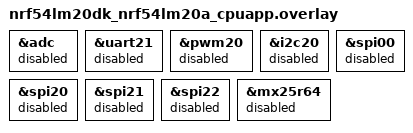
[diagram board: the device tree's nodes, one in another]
/* Copyright (c) 2025 Nordic Semiconductor ASA
 *
 * SPDX-License-Identifier: LicenseRef-Nordic-5-Clause
 */

&adc {
	status = "disabled";
};
&uart21 {
	status = "disabled";
};
&pwm20 {
	status = "disabled";
};
&i2c20 {
	status = "disabled";
};
&spi00 {
	status = "disabled";
};
&spi20 {
	status = "disabled";
};
&spi21 {
	status = "disabled";
};
&spi22 {
	status = "disabled";
};
&mx25r64 {
	status = "disabled";
};
